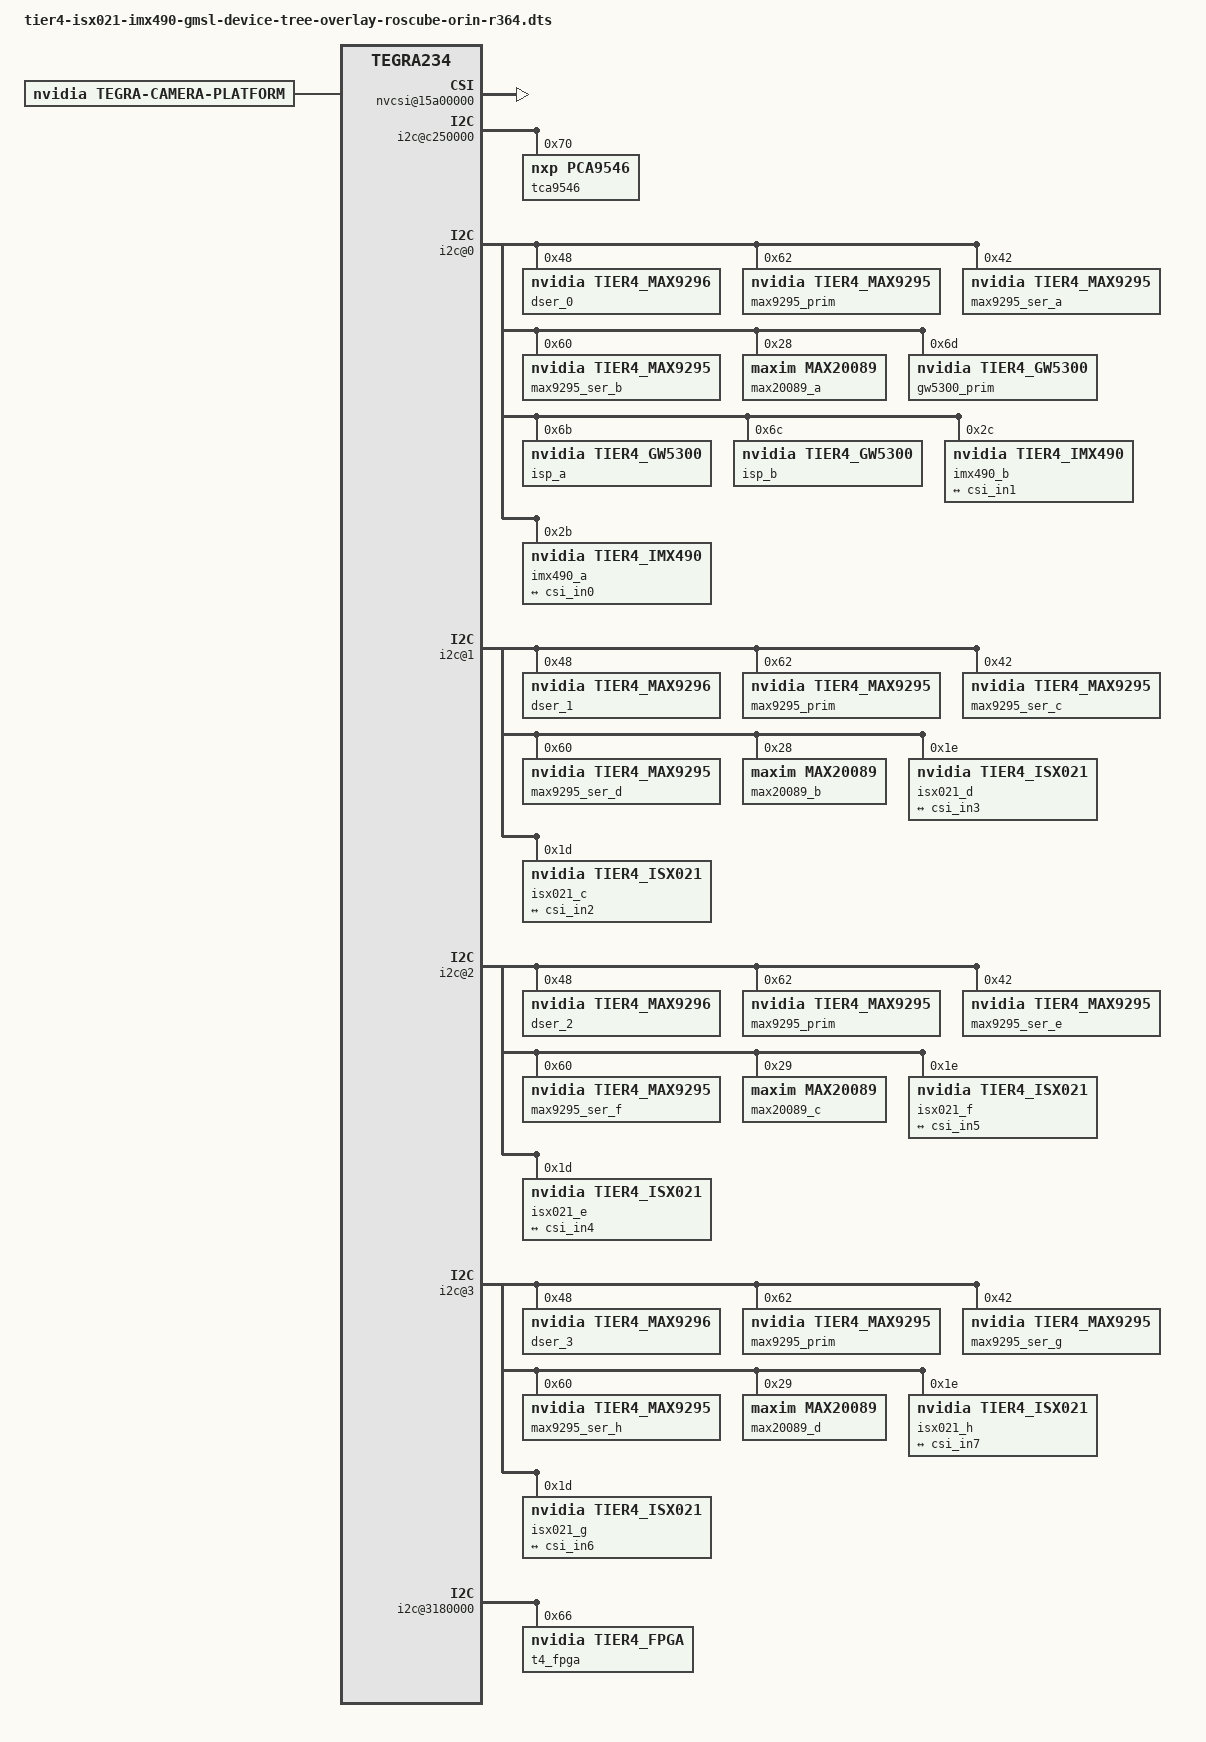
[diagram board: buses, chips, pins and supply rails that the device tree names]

/dts-v1/;
/plugin/;

/ {
    overlay-name = "TIERIV GMSL2 Camera Device Tree Overlay: C2x2 C1x6";
    jetson-header-name = "Jetson AGX CSI Connector";
    compatible = "nvidia,p3737-0000+p3701-0000", "nvidia,tegra234", "nvidia,tegra23x";

// ----- for VI -----

  fragment@1{
    target-path = "/tegra-capture-vi";
    __overlay__ {
      status = "okay";
      num-channels = <0x08>;
      ports {
        status = "okay";
        #address-cells = <1>;
        #size-cells = <0>;
        port@0 {
          status = "okay";
          reg = <0>;
          vi_in0: endpoint {
            status = "okay";
          };
        };
        port@1 {
          status = "okay";
          reg = <1>;
          vi_in1: endpoint {
            status = "okay";
          };
        };
        port@2 {
          status = "okay";
          reg = <2>;
          vi_in2: endpoint {
            status = "okay";
          };
        };
        port@3 {
          status = "okay";
          reg = <3>;
          vi_in3: endpoint {
            status = "okay";
          };
        };
        port@4 {
          status = "okay";
          reg = <4>;
          vi_in4: endpoint {
            status = "okay";
          };
        };
        port@5 {
          status = "okay";
          reg = <5>;
          vi_in5: endpoint {
            status = "okay";
          };
        };
        port@6 {
          status = "okay";
          reg = <6>;
          vi_in6: endpoint {
            status = "okay";
          };
        };
        port@7 {
          status = "okay";
          reg = <7>;
          vi_in7: endpoint {
            status = "okay";
          };
        };
      };
    };
  };

//diff view
  fragment@2{
    target-path = "/tegra-capture-vi/ports/port@0";
    __overlay__ {
      status = "okay";
    };
  };

  fragment@3{
    // target = vi_in0;
    target-path = "/tegra-capture-vi/ports/port@0/endpoint";
    __overlay__ {
      status = "okay";
      port-index = <0>;
      vc-id = <0>;
      bus-width = <4>;
      remote-endpoint = <&csi_out0>;
    };
  };

  fragment@4{
    target-path = "/tegra-capture-vi/ports/port@1";
    __overlay__ {
      status = "okay";
    };
  };

  fragment@5{
    // target = vi_in1;
    target-path = "/tegra-capture-vi/ports/port@1/endpoint";
    __overlay__ {
      status = "okay";
      vc-id = <1>;
      port-index = <0>;
      bus-width = <4>;
      remote-endpoint = <&csi_out1>;
    };
  };

  fragment@6{
    target-path = "/tegra-capture-vi/ports/port@2";
    __overlay__ {
      status = "okay";
    };
  };

  fragment@7{
    // target = vi_in2;
    target-path = "/tegra-capture-vi/ports/port@2/endpoint";
    __overlay__ {
      status = "okay";
      vc-id = <0>;
      port-index = <2>;
      bus-width = <4>;
      remote-endpoint = <&csi_out2>;
    };
  };

  fragment@8 {
    target-path = "/tegra-capture-vi/ports/port@3";
    __overlay__ {
      status = "okay";
    };
  };

  fragment@9 {
    // target = vi_in3;
    target-path = "/tegra-capture-vi/ports/port@3/endpoint";
    __overlay__ {
      status = "okay";
      vc-id = <1>;
      port-index = <2>;
      bus-width = <4>;
      remote-endpoint = <&csi_out3>;
    };
  };

  fragment@10 {
    target-path = "/tegra-capture-vi/ports/port@4";
    __overlay__ {
      status = "okay";
    };
  };

  fragment@11 {
    // target = vi_in4;
    target-path = "/tegra-capture-vi/ports/port@4/endpoint";
    __overlay__ {
      status = "okay";
      vc-id = <0>;
      port-index = <4>;
      bus-width = <4>;
      remote-endpoint = <&csi_out4>;
    };
  };

  fragment@12 {
    target-path = "/tegra-capture-vi/ports/port@5";
    __overlay__ {
      status = "okay";
    };
  };

  fragment@13 {
    // target = vi_in5;
    target-path = "/tegra-capture-vi/ports/port@5/endpoint";
    __overlay__ {
      status = "okay";
      vc-id = <1>;
      port-index = <4>;
      bus-width = <4>;
      remote-endpoint = <&csi_out5>;
    };
  };

  fragment@14 {
    target-path = "/tegra-capture-vi/ports/port@6";
    __overlay__ {
      status = "okay";
    };
  };

  fragment@15 {
    // target = vi_in6;
    target-path = "/tegra-capture-vi/ports/port@6/endpoint";
    __overlay__ {
      status = "okay";
      vc-id = <0>;
      port-index = <5>;
      bus-width = <4>;
      remote-endpoint = <&csi_out6>;
    };
  };

  fragment@16 {
    target-path = "/tegra-capture-vi/ports/port@7";
    __overlay__ {
      status = "okay";
    };
  };

  fragment@17 {
    // target = vi_in7;
    target-path = "/tegra-capture-vi/ports/port@7/endpoint";
    __overlay__ {
      status = "okay";
      vc-id = <1>;
      port-index = <5>;
      bus-width = <4>;
      remote-endpoint = <&csi_out7>;
    };
  };

// -----   NVCSI  ------

  fragment@19 {
    target-path = "/bus@0/host1x@13e00000/nvcsi@15a00000";
    __overlay__ {
        status = "okay";
        #address-cells = <1>;
        #size-cells = <0>;
        num-channels = <8>;
        channel@0 {
          status = "okay";
          reg = <0>;
          ports {
            status = "okay";
            #address-cells = <1>;
            #size-cells = <0>;
            port@0 {
              status = "okay";
              reg = <0>;
              csi_in0: endpoint@0 {
                status = "okay";
              };
            };
            port@1 {
              status = "okay";
              reg = <1>;
              csi_out0: endpoint@1 {
                status = "okay";
              };
            };
          };
        };
        channel@1 {
          status = "okay";
          reg = <1>;
          ports {
            status = "okay";
            #address-cells = <1>;
            #size-cells = <0>;
            port@0 {
              status = "okay";
              reg = <0>;
              csi_in1: endpoint@0 {
                status = "okay";
              };
            };
            port@1 {
              status = "okay";
              reg = <1>;
              csi_out1: endpoint@1 {
                status = "okay";
              };
            };
          };
        };
        channel@2 {
          status = "okay";
          reg = <2>;
          ports {
            status = "okay";
            #address-cells = <1>;
            #size-cells = <0>;
            port@0 {
              status = "okay";
              reg = <0>;
              csi_in2: endpoint@0 {
                status = "okay";
              };
            };
            port@1 {
              status = "okay";
              reg = <1>;
              csi_out2: endpoint@1 {
                status = "okay";
              };
            };
          };
        };
        channel@3 {
          status = "okay";
          reg = <3>;
          ports {
            status = "okay";
            #address-cells = <1>;
            #size-cells = <0>;
            port@0 {
              status = "okay";
              reg = <0>;
              csi_in3: endpoint@0 {
                status = "okay";
              };
            };
            port@1 {
              status = "okay";
              reg = <1>;
              csi_out3: endpoint@1 {
                status = "okay";
              };
            };
          };
        };
        channel@4 {
          status = "okay";
          reg = <4>;
          ports {
            status = "okay";
            #address-cells = <1>;
            #size-cells = <0>;
            port@0 {
              status = "okay";
              reg = <0>;
              csi_in4: endpoint@0 {
                status = "okay";
              };
            };
            port@1 {
              status = "okay";
              reg = <1>;
              csi_out4: endpoint@1 {
                status = "okay";
              };
            };
          };
        };
        channel@5 {
          status = "okay";
          reg = <5>;
          ports {
            status = "okay";
            #address-cells = <1>;
            #size-cells = <0>;
            port@0 {
              status = "okay";
              reg = <0>;
              csi_in5: endpoint@0 {
                status = "okay";
              };
            };
            port@1 {
              status = "okay";
              reg = <1>;
              csi_out5: endpoint@1 {
                status = "okay";
              };
            };
          };
        };
        channel@6 {
          status = "okay";
          reg = <6>;
          ports {
            status = "okay";
            #address-cells = <1>;
            #size-cells = <0>;
            port@0 {
              status = "okay";
              reg = <0>;
              csi_in6: endpoint@0 {
                status = "okay";
              };
            };
            port@1 {
              status = "okay";
              reg = <1>;
              csi_out6: endpoint@1 {
                status = "okay";
              };
            };
          };
        };
        channel@7 {
          status = "okay";
          reg = <7>;
          ports {
            status = "okay";
            #address-cells = <1>;
            #size-cells = <0>;
            port@0 {
              status = "okay";
              reg = <0>;
              csi_in7: endpoint@0 {
                status = "okay";
              };
            };
            port@1 {
              status = "okay";
              reg = <1>;
              csi_out7: endpoint@1 {
                status = "okay";
              };
            };
          };
        };
    };
  };


// channel@0

  fragment@20 {
    target-path = "/bus@0/host1x@13e00000/nvcsi@15a00000/channel@0";
    __overlay__ {
      status = "okay";
    };
  };

  fragment@21 {
    target-path = "/bus@0/host1x@13e00000/nvcsi@15a00000/channel@0/ports/port@0";
    __overlay__ {
      status = "okay";
    };
  };
  fragment@22 {
    // target = csi_in0
    target-path = "/bus@0/host1x@13e00000/nvcsi@15a00000/channel@0/ports/port@0/endpoint@0";
    __overlay__ {
      status = "okay";
      port-index = <0>;
      bus-width = <4>;
      remote-endpoint = <&imx490_out0>;
    };
  };

  fragment@23 {
    target-path = "/bus@0/host1x@13e00000/nvcsi@15a00000/channel@0/ports/port@1";
    __overlay__ {
      status = "okay";
    };
  };

  fragment@24 {
    // target = csi_out0
    target-path = "/bus@0/host1x@13e00000/nvcsi@15a00000/channel@0/ports/port@1/endpoint@1";
    __overlay__ {
      status = "okay";
      remote-endpoint = <&vi_in0>;
    };
  };

// channel@1

  fragment@25 {
    target-path = "/bus@0/host1x@13e00000/nvcsi@15a00000/channel@1";
    __overlay__ {
      status = "okay";
    };
  };

  fragment@26 {
    target-path = "/bus@0/host1x@13e00000/nvcsi@15a00000/channel@1/ports/port@0";
    __overlay__ {
      status = "okay";
    };
  };

  fragment@27 {
    // target = csi_in1
    target-path = "/bus@0/host1x@13e00000/nvcsi@15a00000/channel@1/ports/port@0/endpoint@0";
    __overlay__ {
      status = "okay";
      port-index = <0>;
      bus-width = <4>;
      remote-endpoint = <&imx490_out1>;
    };
  };

  fragment@28 {
    // target = csi_out1
    target-path = "/bus@0/host1x@13e00000/nvcsi@15a00000/channel@1/ports/port@1/endpoint@1";
    __overlay__ {
      status = "okay";
      remote-endpoint = <&vi_in1>;
    };
  };

// channel@2

  fragment@29 {
    target-path = "/bus@0/host1x@13e00000/nvcsi@15a00000/channel@2";
    __overlay__ {
      status = "okay";
    };
  };

  fragment@30 {
    target-path = "/bus@0/host1x@13e00000/nvcsi@15a00000/channel@2/ports/port@0";
    __overlay__ {
      status = "okay";
    };
  };

  fragment@31 {
    // target = csi_in2
    target-path = "/bus@0/host1x@13e00000/nvcsi@15a00000/channel@2/ports/port@0/endpoint@0";
    __overlay__ {
      status = "okay";
      port-index = <2>;
      bus-width = <4>;
      remote-endpoint = <&isx021_out2>;
    };
  };

  fragment@32 {
    target-path = "/bus@0/host1x@13e00000/nvcsi@15a00000/channel@2/ports/port@1";
    __overlay__ {
      status = "okay";
    };
  };

  fragment@33 {
    // target = csi_out2
    target-path = "/bus@0/host1x@13e00000/nvcsi@15a00000/channel@2/ports/port@1/endpoint@1";
    __overlay__ {
      status = "okay";
      remote-endpoint = <&vi_in2>;
    };
  };

// channel@3

  fragment@34 {
    target-path = "/bus@0/host1x@13e00000/nvcsi@15a00000/channel@3";
    __overlay__ {
      status = "okay";
    };
  };

  fragment@35 {
    target-path = "/bus@0/host1x@13e00000/nvcsi@15a00000/channel@3/ports/port@0";
    __overlay__ {
      status = "okay";
    };
  };

  fragment@36 {
    // target = csi_in3
    target-path = "/bus@0/host1x@13e00000/nvcsi@15a00000/channel@3/ports/port@0/endpoint@0";
    __overlay__ {
      status = "okay";
      port-index = <2>;
      bus-width = <4>;
      remote-endpoint = <&isx021_out3>;
    };
  };

  fragment@37 {
    target-path = "/bus@0/host1x@13e00000/nvcsi@15a00000/channel@3/ports/port@1";
    __overlay__ {
      status = "okay";
    };
  };

  fragment@38 {
    // target = csi_out3
    target-path = "/bus@0/host1x@13e00000/nvcsi@15a00000/channel@3/ports/port@1/endpoint@1";
    __overlay__ {
      status = "okay";
      remote-endpoint = <&vi_in3>;
    };
  };

// channel@4

  fragment@39 {
    target-path = "/bus@0/host1x@13e00000/nvcsi@15a00000/channel@4";
    __overlay__ {
      status = "okay";
    };
  };

  fragment@40 {
    target-path = "/bus@0/host1x@13e00000/nvcsi@15a00000/channel@4/ports/port@0";
    __overlay__ {
      status = "okay";
    };
  };

  fragment@41 {
    // target = csi_in4
    target-path = "/bus@0/host1x@13e00000/nvcsi@15a00000/channel@4/ports/port@0/endpoint@0";
    __overlay__ {
      status = "okay";
      port-index = <4>;
      bus-width = <4>;
      remote-endpoint = <&isx021_out4>;
    };
  };

  fragment@42 {
    target-path = "/bus@0/host1x@13e00000/nvcsi@15a00000/channel@4/ports/port@1";
    __overlay__ {
      status = "okay";
    };
  };

  fragment@43 {
    // target = csi_out4
    target-path = "/bus@0/host1x@13e00000/nvcsi@15a00000/channel@4/ports/port@1/endpoint@1";
    __overlay__ {
      status = "okay";
      remote-endpoint = <&vi_in4>;
    };
  };

// channel@5

  fragment@44 {
    target-path = "/bus@0/host1x@13e00000/nvcsi@15a00000/channel@5";
    __overlay__ {
      status = "okay";
    };
  };

  fragment@45 {
    target-path = "/bus@0/host1x@13e00000/nvcsi@15a00000/channel@5/ports/port@0";
    __overlay__ {
      status = "okay";
    };
  };

  fragment@46 {
    // target = csi_in5
    target-path = "/bus@0/host1x@13e00000/nvcsi@15a00000/channel@5/ports/port@0/endpoint@0";
    __overlay__ {
      status = "okay";
      port-index = <4>;
      bus-width = <4>;
      remote-endpoint = <&isx021_out5>;
    };
  };

  fragment@47 {
    target-path = "/bus@0/host1x@13e00000/nvcsi@15a00000/channel@5/ports/port@1";
    __overlay__ {
      status = "okay";
    };
  };

  fragment@48 {
    // target = csi_out5
    target-path = "/bus@0/host1x@13e00000/nvcsi@15a00000/channel@5/ports/port@1/endpoint@1";
    __overlay__ {
      status = "okay";
      remote-endpoint = <&vi_in5>;
    };
  };

// channel@6

  fragment@49 {
    // target = csi_in6
    target-path = "/bus@0/host1x@13e00000/nvcsi@15a00000/channel@6/ports/port@0/endpoint@0";
    __overlay__ {
      status = "okay";
      port-index = <6>;
      bus-width = <4>;
      remote-endpoint = <&isx021_out6>;
    };
  };

  fragment@50 {
    target-path = "/bus@0/host1x@13e00000/nvcsi@15a00000/channel@6/ports/port@1";
    __overlay__ {
      status = "okay";
    };
  };

  fragment@51 {
    // target = csi_out6
    target-path = "/bus@0/host1x@13e00000/nvcsi@15a00000/channel@6/ports/port@1/endpoint@1";
    __overlay__ {
      status = "okay";
      remote-endpoint = <&vi_in6>;
    };
  };

// channel@7

  fragment@52 {
    // target = csi_in7
    target-path = "/bus@0/host1x@13e00000/nvcsi@15a00000/channel@7/ports/port@0/endpoint@0";
    __overlay__ {
      status = "okay";
      port-index = <6>;
      bus-width = <4>;
      remote-endpoint = <&isx021_out7>;
    };
  };

  fragment@53 {
    target-path = "/bus@0/host1x@13e00000/nvcsi@15a00000/channel@7/ports/port@1";
    __overlay__ {
      status = "okay";
    };
  };

  fragment@54 {
    // target = csi_out7
    target-path = "/bus@0/host1x@13e00000/nvcsi@15a00000/channel@7/ports/port@1/endpoint@1";
    __overlay__ {
      status = "okay";
      remote-endpoint = <&vi_in7>;
    };
  };

  fragment@55 {
    target-path = "/bus@0/host1x@13e00000/nvcsi@15a00000";
    __overlay__ {
      status = "okay";
      num-channels = <8>;
    };
  };

 fragment@56{
   target-path = "/bus@0/host1x@13e00000/vi1@14c00000";
   __overlay__ {
     status = "okay";
   };
 };

  fragment@57{
    target-path = "/bus@0/host1x@13e00000/vi0@15c00000";
    __overlay__ {
      status = "okay";
    };
  };



// ----- Camera modules -----

  fragment@70 {
    //tcp
    target-path = "/";
    __overlay__ {
        tegra-camera-platform {
          compatible = "nvidia, tegra-camera-platform";
          status = "okay";
          num_csi_lanes = <16>;
          max_lane_speed = <4000000>;
          min_bits_per_pixel = <10>;
          vi_peak_byte_per_pixel = <2>;
          vi_bw_margin_pct = <25>;
          max_pixel_rate = <160000>;
          isp_peak_byte_per_pixel = <5>;
          isp_bw_margin_pct = <25>;

          modules {
            module0 {
              drivernode0 {
              };
            };
            module1 {
              drivernode0 {
              };
            };
            module2 {
              drivernode0 {
              };
            };
            module3 {
              drivernode0 {
              };
            };
            module4 {
              drivernode0 {
              };
            };
            module5 {
              drivernode0 {
              };
            };
            module6 {
              drivernode0 {
              };
            };
            module7 {
              drivernode0 {
              };
            };
          };
        };
    };
  };

  fragment@71 {
    target-path = "/tegra-camera-platform/modules/module0";
    __overlay__ {
      badge = "imx490_rear";
      position = "rear";
      orientation = "1";
      status = "okay";
    };
  };

  fragment@72 {
    target-path = "/tegra-camera-platform/modules/module0/drivernode0";
    __overlay__ {
      status = "okay";
      pcl_id = "v4l2_sensor";
      sysfs-device-tree = "/sys/firmware/devicetree/base/bus@0/i2c@c250000/tca9546@70/i2c@0/imx490_a@2b";
    };
  };

  fragment@73 {
    target-path = "/tegra-camera-platform/modules/module1";
    __overlay__ {
      badge = "imx490_front";
      position = "front";
      orientation = "1";
      status = "okay";
    };
  };

  fragment@74 {
    target-path = "/tegra-camera-platform/modules/module1/drivernode0";
    __overlay__ {
      status = "okay";
      pcl_id = "v4l2_sensor";
      sysfs-device-tree = "/sys/firmware/devicetree/base/bus@0/i2c@c250000/tca9546@70/i2c@0/imx490_b@2c";
    };
  };

  fragment@75 {
    target-path = "/tegra-camera-platform/modules/module2";
    __overlay__ {
      badge = "isx021_topright";
      position = "topright";
      orientation = "1";
      status = "okay";
    };
  };

  fragment@76 {
    target-path = "/tegra-camera-platform/modules/module2/drivernode0";
    __overlay__ {
      status = "okay";
      pcl_id = "v4l2_sensor";
      sysfs-device-tree = "/sys/firmware/devicetree/base/bus@0/i2c@c250000/tca9546@70/i2c@1/isx021_c@1d";
    };
  };

  fragment@77 {
    target-path = "/tegra-camera-platform/modules/module3";
    __overlay__ {
      badge = "isx021_bottomright";
      position = "bottomright";
      orientation = "1";
      status = "okay";
    };
  };

  fragment@78 {
    target-path = "/tegra-camera-platform/modules/module3/drivernode0";
    __overlay__ {
      status = "okay";
      pcl_id = "v4l2_sensor";
      sysfs-device-tree = "/sys/firmware/devicetree/base/bus@0/i2c@c250000/tca9546@70/i2c@1/isx021_d@1e";
    };
  };

  fragment@79 {
    target-path = "/tegra-camera-platform/modules/module4";
    __overlay__ {
      badge = "isx021_topleft";
      position = "topleft";
      orientation = "1";
      status = "okay";
    };
  };

  fragment@80 {
    target-path = "/tegra-camera-platform/modules/module4/drivernode0";
    __overlay__ {
      status = "okay";
      pcl_id = "v4l2_sensor";
      sysfs-device-tree = "/sys/firmware/devicetree/base/bus@0/i2c@c250000/tca9546@70/i2c@2/isx021_e@1d";
    };
  };

  fragment@81 {
    target-path = "/tegra-camera-platform/modules/module5";
    __overlay__ {
      badge = "isx021_centerright";
      position = "centerright";
      orientation = "1";
      status = "okay";
    };
  };

  fragment@82 {
    target-path = "/tegra-camera-platform/modules/module5/drivernode0";
    __overlay__ {
      status = "okay";
      pcl_id = "v4l2_sensor";
      sysfs-device-tree = "/sys/firmware/devicetree/base/bus@0/i2c@c250000/tca9546@70/i2c@2/isx021_f@1e";
    };
  };

  fragment@83 {
    target-path = "/tegra-camera-platform/modules/module6";
    __overlay__ {
      badge = "isx021_centerleft";
      position = "centerleft";
      orientation = "1";
      status = "okay";
    };
  };

  fragment@84 {
    target-path = "/tegra-camera-platform/modules/module6/drivernode0";
    __overlay__ {
      status = "okay";
      pcl_id = "v4l2_sensor";
      sysfs-device-tree = "/sys/firmware/devicetree/base/bus@0/i2c@c250000/tca9546@70/i2c@3/isx021_g@1d";
    };
  };

  fragment@85 {
    target-path = "/tegra-camera-platform/modules/module7";
    __overlay__ {
      badge = "isx021_bottomleftt";
      position = "bottomleft";
      orientation = "1";
      status = "okay";
    };
  };

  fragment@86 {
    target-path = "/tegra-camera-platform/modules/module7/drivernode0";
    __overlay__ {
      status = "okay";
      pcl_id = "v4l2_sensor";
      sysfs-device-tree = "/sys/firmware/devicetree/base/bus@0/i2c@c250000/tca9546@70/i2c@3/isx021_h@1e";
    };
  };


  fragment@90 {
    // declare the i2c switch for the four i2c clients
    target-path = "/bus@0/i2c@c250000";
    __overlay__ {
      tca9546@70 {
        status = "okay";
        #address-cells = <1>;
        #size-cells = <0>;
        compatible = "nxp,pca9546";
        reg = <0x70>;
        skip_mux_detect = "yes";
        force_bus_start = <0x1e>;
        i2c@0 {
          status = "okay";
          reg = <0>;
        };
        i2c@1 {
          status = "okay";
          reg = <1>;
        };
        i2c@2 {
          status = "okay";
          reg = <2>;
        };
        i2c@3 {
          status = "okay";
          reg = <3>;
        };
      };
    };
  };

  fragment@91{
    //cami2c/i2c@0
    target-path = "/bus@0/i2c@c250000/tca9546@70/i2c@0";
    __overlay__ {
      i2c-mux,deselect-on-exit;
      #address-cells = <1>;
      #size-cells = <0>;
      status = "okay";
      reg = <0>;

      dser_0: max9296@48 {
        compatible = "nvidia,tier4_max9296";
        reg = <0x48>;
        status = "okay";
        csi-mode = "2x4";
        max-src = <2>;
        //reset-gpios = <&tegra_main_gpio CAM0_PWDN GPIO_ACTIVE_HIGH>;
        //reset-gpios = <&tegra_main_gpio 0x3E 0x0>;
      };

      max9295_prim@62 {
        compatible = "nvidia,tier4_max9295";
        status = "okay";
        reg = <0x62>;
        is-prim-ser;
      };
      max9295_ser_a: max9295_a@42 {
        compatible = "nvidia,tier4_max9295";
        reg = <0x42>;
        nvidia,gmsl-dser-device = <&dser_0>;
      };

      max9295_ser_b: max9295_b@60 {
        compatible = "nvidia,tier4_max9295";
        status = "okay";
        reg = <0x60>;
        nvidia,gmsl-dser-device = <&dser_0>;
      };

      max20089_a: max20089@28 {
        status = "okay";
        compatible = "maxim,max20089";
        reg = <0x28>;
      };

      gw5300_prim@6d {
          compatible = "nvidia,tier4_gw5300";
          reg = <0x6d>;
          is-prim-isp;
      };

      isp_a: gw5300_a@6b {
          compatible = "nvidia,tier4_gw5300";
          reg = <0x6b>;
      };

      isp_b: gw5300_b@6c {
          compatible = "nvidia,tier4_gw5300";
          reg = <0x6c>;
      };

      imx490_b@2c {
        status = "okay";
        compatible = "nvidia,tier4_imx490";
        reg = <0x2c>;
        def-addr = <0x1a>;
        mclk = "extperiph1";
        clocks = <&bpmp 36U>, <&bpmp 36U>;
        clock-names = "extperiph1", "pllp_grtba";
        nvidia,isp-device = <&isp_b>;           // for C2/C3 camera
        nvidia,gmsl-ser-device = <&max9295_ser_b>;
        nvidia,gmsl-dser-device = <&dser_0>;
        nvidia,fpga-device  = <&t4_fpga>;
        nvidia,cam-power-protector  = <&max20089_a>;
        physical_w = "15.0";
        physical_h = "12.5";
        reg_mux = <0>;

        sensor_model ="imx490";
        fsync-mode = "false";
        distortion-correction = "false";
        auto-exposure = "true";
        post_crop_frame_drop = "0";
        use_decibel_gain = "true";

        /* enable CID_SENSOR_MODE_ID for sensor modes selection */
        use_sensor_mode_id = "true";

        mode0 {/*mode IMX490_MODE_2880X1860_CROP_30FPS*/
          mclk_khz = "24000";
          num_lanes = "4";
          tegra_sinterface = "serial_a";
          vc_id = "1";
          discontinuous_clk = "no";
          dpcm_enable = "false";
          cil_settletime = "0";
          dynamic_pixel_bit_depth = "16";
          csi_pixel_bit_depth = "16";
          mode_type = "yuv";
          pixel_phase = "uyvy";

          active_w = "2880";
          active_h = "1860";
          readout_orientation = "0";
          line_length = "2250";
          inherent_gain = "1";
          pix_clk_hz = "757";
          serdes_pix_clk_hz = "375000000";    // MIPI CSI clock 1500Mhz

          gain_factor = "10";
          min_gain_val = "0";                         /* dB */
          max_gain_val = "300";                       /* dB */
          step_gain_val = "3";                        /* 0.3 */
          default_gain = "0";
          min_hdr_ratio = "1";
          max_hdr_ratio = "1";
          framerate_factor = "1000000";
          min_framerate = "30000000";
          max_framerate = "30000000";
          step_framerate = "1";
          default_framerate = "30000000";
          exposure_factor = "1000000";
          min_exp_time = "24";                         /* us 1 line */
          max_exp_time = "33333";
          step_exp_time = "1";
          default_exp_time = "33333";                 /* us */
          embedded_metadata_height = "0";
        };

        ports {
          #address-cells = <1>;
          #size-cells = <0>;
          port@0 {
            reg = <0>;
            imx490_out1: endpoint {
              vc-id = <1>;
              port-index = <0>;
              bus-width = <4>;
              remote-endpoint = <&csi_in1>;
            };
          };
        };
        gmsl-link {
          src-csi-port = "b";     /* Port at which sensor is connected to its serializer device. */
          dst-csi-port = "a";     /* Destination CSI port on the Jetson side, connected at deserializer. */
           serdes-csi-link = "b";  /* GMSL link sensor/serializer connected */
          csi-mode = "1x4";       /*  to sensor CSI mode. */
          st-vc = <0>;            /* Sensor source default VC ID: 0 unless overridden by sensor. */
          vc-id = <1>;            /* Destination VC ID, assigned to sensor stream by deserializer. */
          num-lanes = <4>;        /* Number of CSI lanes used. */
          streams = "ued-u1","yuv8"; /* Types of streams sensor is streaming. */
        };
      };
      imx490_a@2b {
        status = "okay";
        compatible = "nvidia,tier4_imx490";
        reg = <0x2b>;
        def-addr = <0x1a>;
        mclk = "extperiph1";
        clocks = <&bpmp 36U>, <&bpmp 36U>;
        clock-names = "extperiph1", "pllp_grtba";
        nvidia,isp-device = <&isp_a>;           // for C2/C3 camera
        nvidia,gmsl-ser-device = <&max9295_ser_a>;
        nvidia,gmsl-dser-device = <&dser_0>;
        nvidia,fpga-device  = <&t4_fpga>;
        nvidia,cam-power-protector  = <&max20089_a>;
        physical_w = "15.0";
        physical_h = "12.5";
        reg_mux = <0>;

        sensor_model ="imx490";
        fsync-mode = "false";
        distortion-correction = "false";
        auto-exposure = "true";
        post_crop_frame_drop = "0";
        use_decibel_gain = "true";

        /* enable CID_SENSOR_MODE_ID for sensor modes selection */
        use_sensor_mode_id = "true";

        mode0 {/*mode IMX490_MODE_2880X1860_CROP_30FPS*/
          mclk_khz = "24000";
          num_lanes = "4";
          tegra_sinterface = "serial_a";
          vc_id = "0";
          discontinuous_clk = "no";
          dpcm_enable = "false";
          cil_settletime = "0";
          dynamic_pixel_bit_depth = "16";
          csi_pixel_bit_depth = "16";
          mode_type = "yuv";
          pixel_phase = "uyvy";

          active_w = "2880";
          active_h = "1860";
          readout_orientation = "0";
          line_length = "2250";
          inherent_gain = "1";
          pix_clk_hz = "757";
          serdes_pix_clk_hz = "375000000";    // MIPI CSI clock 1500Mhz

          gain_factor = "10";
          min_gain_val = "0";                         /* dB */
          max_gain_val = "300";                       /* dB */
          step_gain_val = "3";                        /* 0.3 */
          default_gain = "0";
          min_hdr_ratio = "1";
          max_hdr_ratio = "1";
          framerate_factor = "1000000";
          min_framerate = "30000000";
          max_framerate = "30000000";
          step_framerate = "1";
          default_framerate = "30000000";
          exposure_factor = "1000000";
          min_exp_time = "24";                         /* us 1 line */
          max_exp_time = "33333";
          step_exp_time = "1";
          default_exp_time = "33333";                 /* us */
          embedded_metadata_height = "0";
        };

        ports {
          #address-cells = <1>;
          #size-cells = <0>;
          port@0 {
            reg = <0>;
            imx490_out0: endpoint {
              vc-id = <0>;
              port-index = <0>;
              bus-width = <4>;
              remote-endpoint = <&csi_in0>;
            };
          };
        };
        gmsl-link {
          src-csi-port = "b";     /* Port at which sensor is connected to its serializer device. */
          dst-csi-port = "a";     /* Destination CSI port on the Jetson side, connected at deserializer. */
          serdes-csi-link = "a";  /* GMSL link sensor/serializer connected */
          csi-mode = "1x4";       /*  to sensor CSI mode. */
          st-vc = <0>;            /* Sensor source default VC ID: 0 unless overridden by sensor. */
          vc-id = <0>;            /* Destination VC ID, assigned to sensor stream by deserializer. */
          num-lanes = <4>;        /* Number of CSI lanes used. */
          streams = "ued-u1","yuv8"; /* Types of streams sensor is streaming. */
        };
      };
    };
  };
  fragment@92{
    //cami2c/i2c@1
    target-path = "/bus@0/i2c@c250000/tca9546@70/i2c@1";
    __overlay__ {
      i2c-mux,deselect-on-exit;
      #address-cells = <1>;
      #size-cells = <0>;
      status = "okay";
      reg = <1>;

      dser_1: max9296@48 {
        compatible = "nvidia,tier4_max9296";
        reg = <0x48>;
        status = "okay";
        csi-mode = "2x4";
        max-src = <2>;
        //reset-gpios = <&tegra_main_gpio CAM0_PWDN GPIO_ACTIVE_HIGH>;
        //reset-gpios = <&tegra_main_gpio 0x3E 0x0>;
      };

      max9295_prim@62 {
        compatible = "nvidia,tier4_max9295";
        status = "okay";
        reg = <0x62>;
        is-prim-ser;
      };
      max9295_ser_c: max9295_a@42 {
        compatible = "nvidia,tier4_max9295";
        reg = <0x42>;
        nvidia,gmsl-dser-device = <&dser_1>;
      };

      max9295_ser_d: max9295_b@60 {
        compatible = "nvidia,tier4_max9295";
        status = "okay";
        reg = <0x60>;
        nvidia,gmsl-dser-device = <&dser_1>;
      };

      max20089_b: max20089@28 {
        status = "okay";
        compatible = "maxim,max20089";
        reg = <0x28>;
      };

      isx021_d@1e {
        status = "okay";
        compatible = "nvidia,tier4_isx021";
        def-addr = <0x1a>;
        mclk = "extperiph1";
        clocks = <&bpmp 36U>, <&bpmp 36U>;
        clock-names = "extperiph1", "pllp_grtba";
        nvidia,gmsl-ser-device = <&max9295_ser_d>;
        nvidia,gmsl-dser-device = <&dser_1>;
        nvidia,fpga-device  = <&t4_fpga>;
        nvidia,cam-power-protector  = <&max20089_b>;
        reg = <0x1e>;
        physical_w = "15.0";
        physical_h = "12.5";
        reg_mux = <1>;

        sensor_model ="isx021";
        fsync-mode = "false";
        distortion-correction = "false";
        auto-exposure = "true";
        post_crop_frame_drop = "0";
        use_decibel_gain = "true";

        /* enable CID_SENSOR_MODE_ID for sensor modes selection */
        use_sensor_mode_id = "false";

        mode0 {
          /*mode ISX021_MODE_1920X1280_CROP_30FPS*/
          mclk_khz = "24000";
          num_lanes = "4";
          tegra_sinterface = "serial_c";
          vc_id = "1";
          discontinuous_clk = "no";
          dpcm_enable = "false";
          cil_settletime = "0";
          dynamic_pixel_bit_depth = "16";
          csi_pixel_bit_depth = "16";
          mode_type = "yuv";
          pixel_phase = "uyvy";

          active_w = "1920";
          active_h = "1280";
          readout_orientation = "0";
          line_length = "2250";
          inherent_gain = "1";

          pix_clk_hz = "94500000";
          serdes_pix_clk_hz = "375000000";    // MIPI CSI clock 1500Mhz

          gain_factor = "10";
          min_gain_val = "0";                   /* dB */
          max_gain_val = "300";                 /* dB */
          step_gain_val = "3";                  /* 0.3 */
          default_gain = "0";
          min_hdr_ratio = "1";
          max_hdr_ratio = "1";
          framerate_factor = "1000000";
          min_framerate = "30000000";
          max_framerate = "30000000";
          step_framerate = "1";
          default_framerate = "30000000";
          exposure_factor = "1000000";
          min_exp_time = "24";                  /* us 1 line */
          max_exp_time = "33333";
          step_exp_time = "1";
          default_exp_time = "33333";           /* us */
          embedded_metadata_height = "0";
        };
        mode1 {
          /*mode ISX021_MODE_1920X1280_CROP_30FPS  for Front Embedded data */
          mclk_khz = "24000";
          num_lanes = "4";
          tegra_sinterface = "serial_c";
          vc_id = "1";
          discontinuous_clk = "no";
          dpcm_enable = "false";
          cil_settletime = "0";
          dynamic_pixel_bit_depth = "16";
          csi_pixel_bit_depth = "16";
          mode_type = "yuv";
          pixel_phase = "uyvy";
          active_w = "1920";
          active_h = "1281";
          readout_orientation = "0";
          line_length = "2250";
          inherent_gain = "1";
          pix_clk_hz = "94500000";
          serdes_pix_clk_hz = "375000000";      /* MIPI CSI clock 1500Mhz */
          gain_factor = "10";
          min_gain_val = "0";                   /* dB */
          max_gain_val = "300";                 /* dB */
          step_gain_val = "3";                  /* 0.3 */
          default_gain = "0";
          min_hdr_ratio = "1";
          max_hdr_ratio = "1";
          framerate_factor = "1000000";
          min_framerate = "30000000";
          max_framerate = "30000000";
          step_framerate = "1";
          default_framerate = "30000000";
          exposure_factor = "1000000";
          min_exp_time = "24";                  /* us 1 line */
          max_exp_time = "33333";
          step_exp_time = "1";
          default_exp_time = "33333";           /* us */
          embedded_metadata_height = "0";
        };
        mode2 {
          /*mode ISX021_MODE_1920X1280_CROP_30FPS  for Rear Embedded data */
          mclk_khz = "24000";
          num_lanes = "4";
          tegra_sinterface = "serial_c";
          vc_id = "1";
          discontinuous_clk = "no";
          dpcm_enable = "false";
          cil_settletime = "0";
          dynamic_pixel_bit_depth = "16";
          csi_pixel_bit_depth = "16";
          mode_type = "yuv";
          pixel_phase = "uyvy";
          active_w = "1920";
          active_h = "1294";
          readout_orientation = "0";
          line_length = "2250";
          inherent_gain = "1";
          pix_clk_hz = "94500000";
          serdes_pix_clk_hz = "375000000";      /* MIPI CSI clock 1500Mhz */
          gain_factor = "10";
          min_gain_val = "0";                   /* dB */
          max_gain_val = "300";                 /* dB */
          step_gain_val = "3";                  /* 0.3 */
          default_gain = "0";
          min_hdr_ratio = "1";
          max_hdr_ratio = "1";
          framerate_factor = "1000000";
          min_framerate = "30000000";
          max_framerate = "30000000";
          step_framerate = "1";
          default_framerate = "30000000";
          exposure_factor = "1000000";
          min_exp_time = "24";                  /* us 1 line */
          max_exp_time = "33333";
          step_exp_time = "1";
          default_exp_time = "33333";           /* us */
          embedded_metadata_height = "0";
        };
        mode3 {
          /*mode ISX021_MODE_1920X1280_CROP_30FPS  for Front and Rear Embedded data */
          mclk_khz = "24000";
          num_lanes = "4";
          tegra_sinterface = "serial_c";
          vc_id = "1";
          discontinuous_clk = "no";
          dpcm_enable = "false";
          cil_settletime = "0";
          dynamic_pixel_bit_depth = "16";
          csi_pixel_bit_depth = "16";
          mode_type = "yuv";
          pixel_phase = "uyvy";
          active_w = "1920";
          active_h = "1295";
          readout_orientation = "0";
          line_length = "2250";
          inherent_gain = "1";
          pix_clk_hz = "94500000";
          serdes_pix_clk_hz = "375000000";      /* MIPI CSI clock 1500Mhz */
          gain_factor = "10";
          min_gain_val = "0";                   /* dB */
          max_gain_val = "300";                 /* dB */
          step_gain_val = "3";                  /* 0.3 */
          default_gain = "0";
          min_hdr_ratio = "1";
          max_hdr_ratio = "1";
          framerate_factor = "1000000";
          min_framerate = "30000000";
          max_framerate = "30000000";
          step_framerate = "1";
          default_framerate = "30000000";
          exposure_factor = "1000000";
          min_exp_time = "24";                  /* us 1 line */
          max_exp_time = "33333";
          step_exp_time = "1";
          default_exp_time = "33333";           /* us */
          embedded_metadata_height = "0";
        };

        ports {
          #address-cells = <1>;
          #size-cells = <0>;
          port@0 {
            reg = <0>;
            isx021_out3: endpoint {
              vc-id = <1>;
              port-index = <2>;
              bus-width = <4>;
              remote-endpoint = <&csi_in3>;
            };
          };
        };

        gmsl-link {
          src-csi-port = "b";           /* Port at which sensor is connected to its serializer device. */
          dst-csi-port = "a";           /* Destination CSI port on the Jetson side, connected at deserializer. */
           serdes-csi-link = "b";        /* GMSL link sensor/serializer connected */
          csi-mode = "1x4";             /*  to sensor CSI mode. */
          st-vc = <0>;                  /* Sensor source default VC ID: 0 unless overridden by sensor. */
          vc-id = <1>;                  /* Destination VC ID, assigned to sensor stream by deserializer. */
          num-lanes = <4>;              /* Number of CSI lanes used. */
          streams = "ued-u1", "yuv8";   /* Types of streams sensor is streaming. */
        };
      };
      isx021_c@1d {
        status = "okay";
        compatible = "nvidia,tier4_isx021";
        def-addr = <0x1a>;
        mclk = "extperiph1";
        clocks = <&bpmp 36U>, <&bpmp 36U>;
        clock-names = "extperiph1", "pllp_grtba";
        nvidia,gmsl-ser-device = <&max9295_ser_c>;
        nvidia,gmsl-dser-device = <&dser_1>;
        nvidia,fpga-device  = <&t4_fpga>;
        nvidia,cam-power-protector  = <&max20089_b>;
        reg = <0x1d>;
        physical_w = "15.0";
        physical_h = "12.5";
        reg_mux = <1>;

        sensor_model ="isx021";
        fsync-mode = "false";
        distortion-correction = "false";
        auto-exposure = "true";
        post_crop_frame_drop = "0";
        use_decibel_gain = "true";

        /* enable CID_SENSOR_MODE_ID for sensor modes selection */
        use_sensor_mode_id = "false";

        mode0 {
          /*mode ISX021_MODE_1920X1280_CROP_30FPS*/
          mclk_khz = "24000";
          num_lanes = "4";
          tegra_sinterface = "serial_c";
          vc_id = "0";
          discontinuous_clk = "no";
          dpcm_enable = "false";
          cil_settletime = "0";
          dynamic_pixel_bit_depth = "16";
          csi_pixel_bit_depth = "16";
          mode_type = "yuv";
          pixel_phase = "uyvy";

          active_w = "1920";
          active_h = "1280";
          readout_orientation = "0";
          line_length = "2250";
          inherent_gain = "1";

          pix_clk_hz = "94500000";
          serdes_pix_clk_hz = "375000000";    // MIPI CSI clock 1500Mhz

          gain_factor = "10";
          min_gain_val = "0";                   /* dB */
          max_gain_val = "300";                 /* dB */
          step_gain_val = "3";                  /* 0.3 */
          default_gain = "0";
          min_hdr_ratio = "1";
          max_hdr_ratio = "1";
          framerate_factor = "1000000";
          min_framerate = "30000000";
          max_framerate = "30000000";
          step_framerate = "1";
          default_framerate = "30000000";
          exposure_factor = "1000000";
          min_exp_time = "24";                  /* us 1 line */
          max_exp_time = "33333";
          step_exp_time = "1";
          default_exp_time = "33333";           /* us */
          embedded_metadata_height = "0";
        };
        mode1 {
          /*mode ISX021_MODE_1920X1280_CROP_30FPS  for Front Embedded data */
          mclk_khz = "24000";
          num_lanes = "4";
          tegra_sinterface = "serial_c";
          vc_id = "0";
          discontinuous_clk = "no";
          dpcm_enable = "false";
          cil_settletime = "0";
          dynamic_pixel_bit_depth = "16";
          csi_pixel_bit_depth = "16";
          mode_type = "yuv";
          pixel_phase = "uyvy";
          active_w = "1920";
          active_h = "1281";
          readout_orientation = "0";
          line_length = "2250";
          inherent_gain = "1";
          pix_clk_hz = "94500000";
          serdes_pix_clk_hz = "375000000";      /* MIPI CSI clock 1500Mhz */
          gain_factor = "10";
          min_gain_val = "0";                   /* dB */
          max_gain_val = "300";                 /* dB */
          step_gain_val = "3";                  /* 0.3 */
          default_gain = "0";
          min_hdr_ratio = "1";
          max_hdr_ratio = "1";
          framerate_factor = "1000000";
          min_framerate = "30000000";
          max_framerate = "30000000";
          step_framerate = "1";
          default_framerate = "30000000";
          exposure_factor = "1000000";
          min_exp_time = "24";                  /* us 1 line */
          max_exp_time = "33333";
          step_exp_time = "1";
          default_exp_time = "33333";           /* us */
          embedded_metadata_height = "0";
        };
        mode2 {
          /*mode ISX021_MODE_1920X1280_CROP_30FPS  for Rear Embedded data */
          mclk_khz = "24000";
          num_lanes = "4";
          tegra_sinterface = "serial_c";
          vc_id = "0";
          discontinuous_clk = "no";
          dpcm_enable = "false";
          cil_settletime = "0";
          dynamic_pixel_bit_depth = "16";
          csi_pixel_bit_depth = "16";
          mode_type = "yuv";
          pixel_phase = "uyvy";
          active_w = "1920";
          active_h = "1294";
          readout_orientation = "0";
          line_length = "2250";
          inherent_gain = "1";
          pix_clk_hz = "94500000";
          serdes_pix_clk_hz = "375000000";      /* MIPI CSI clock 1500Mhz */
          gain_factor = "10";
          min_gain_val = "0";                   /* dB */
          max_gain_val = "300";                 /* dB */
          step_gain_val = "3";                  /* 0.3 */
          default_gain = "0";
          min_hdr_ratio = "1";
          max_hdr_ratio = "1";
          framerate_factor = "1000000";
          min_framerate = "30000000";
          max_framerate = "30000000";
          step_framerate = "1";
          default_framerate = "30000000";
          exposure_factor = "1000000";
          min_exp_time = "24";                  /* us 1 line */
          max_exp_time = "33333";
          step_exp_time = "1";
          default_exp_time = "33333";           /* us */
          embedded_metadata_height = "0";
        };
        mode3 {
          /*mode ISX021_MODE_1920X1280_CROP_30FPS  for Front and Rear Embedded data */
          mclk_khz = "24000";
          num_lanes = "4";
          tegra_sinterface = "serial_c";
          vc_id = "0";
          discontinuous_clk = "no";
          dpcm_enable = "false";
          cil_settletime = "0";
          dynamic_pixel_bit_depth = "16";
          csi_pixel_bit_depth = "16";
          mode_type = "yuv";
          pixel_phase = "uyvy";
          active_w = "1920";
          active_h = "1295";
          readout_orientation = "0";
          line_length = "2250";
          inherent_gain = "1";
          pix_clk_hz = "94500000";
          serdes_pix_clk_hz = "375000000";      /* MIPI CSI clock 1500Mhz */
          gain_factor = "10";
          min_gain_val = "0";                   /* dB */
          max_gain_val = "300";                 /* dB */
          step_gain_val = "3";                  /* 0.3 */
          default_gain = "0";
          min_hdr_ratio = "1";
          max_hdr_ratio = "1";
          framerate_factor = "1000000";
          min_framerate = "30000000";
          max_framerate = "30000000";
          step_framerate = "1";
          default_framerate = "30000000";
          exposure_factor = "1000000";
          min_exp_time = "24";                  /* us 1 line */
          max_exp_time = "33333";
          step_exp_time = "1";
          default_exp_time = "33333";           /* us */
          embedded_metadata_height = "0";
        };

        ports {
          #address-cells = <1>;
          #size-cells = <0>;
          port@0 {
            reg = <0>;
            isx021_out2: endpoint {
              vc-id = <0>;
              port-index = <2>;
              bus-width = <4>;
              remote-endpoint = <&csi_in2>;
            };
          };
        };

        gmsl-link {
          src-csi-port = "b";           /* Port at which sensor is connected to its serializer device. */
          dst-csi-port = "a";           /* Destination CSI port on the Jetson side, connected at deserializer. */
          serdes-csi-link = "a";        /* GMSL link sensor/serializer connected */
          csi-mode = "1x4";             /*  to sensor CSI mode. */
          st-vc = <0>;                  /* Sensor source default VC ID: 0 unless overridden by sensor. */
          vc-id = <0>;                  /* Destination VC ID, assigned to sensor stream by deserializer. */
          num-lanes = <4>;              /* Number of CSI lanes used. */
          streams = "ued-u1", "yuv8";   /* Types of streams sensor is streaming. */
        };
      };
    };
  };
  fragment@93{
    //cami2c/i2c@2
    target-path = "/bus@0/i2c@c250000/tca9546@70/i2c@2";
    __overlay__ {
      i2c-mux,deselect-on-exit;
      #address-cells = <1>;
      #size-cells = <0>;
      status = "okay";
      reg = <2>;

      dser_2: max9296@48 {
        compatible = "nvidia,tier4_max9296";
        reg = <0x48>;
        status = "okay";
        csi-mode = "2x4";
        max-src = <2>;
        //reset-gpios = <&tegra_main_gpio CAM0_PWDN GPIO_ACTIVE_HIGH>;
        //reset-gpios = <&tegra_main_gpio 0x3E 0x0>;
      };

      max9295_prim@62 {
        compatible = "nvidia,tier4_max9295";
        status = "okay";
        reg = <0x62>;
        is-prim-ser;
      };
      max9295_ser_e: max9295_a@42 {
        compatible = "nvidia,tier4_max9295";
        reg = <0x42>;
        nvidia,gmsl-dser-device = <&dser_2>;
      };

      max9295_ser_f: max9295_b@60 {
        compatible = "nvidia,tier4_max9295";
        status = "okay";
        reg = <0x60>;
        nvidia,gmsl-dser-device = <&dser_2>;
      };

      max20089_c: max20089@29 {
        status = "okay";
        compatible = "maxim,max20089";
        reg = <0x29>;
      };

      isx021_f@1e {
        status = "okay";
        compatible = "nvidia,tier4_isx021";
        def-addr = <0x1a>;
        mclk = "extperiph1";
        clocks = <&bpmp 36U>, <&bpmp 36U>;
        clock-names = "extperiph1", "pllp_grtba";
        nvidia,gmsl-ser-device = <&max9295_ser_f>;
        nvidia,gmsl-dser-device = <&dser_2>;
        nvidia,fpga-device  = <&t4_fpga>;
        nvidia,cam-power-protector  = <&max20089_c>;
        reg = <0x1e>;
        physical_w = "15.0";
        physical_h = "12.5";
        reg_mux = <2>;

        sensor_model ="isx021";
        fsync-mode = "false";
        distortion-correction = "false";
        auto-exposure = "true";
        post_crop_frame_drop = "0";
        use_decibel_gain = "true";

        /* enable CID_SENSOR_MODE_ID for sensor modes selection */
        use_sensor_mode_id = "false";

        mode0 {
          /*mode ISX021_MODE_1920X1280_CROP_30FPS*/
          mclk_khz = "24000";
          num_lanes = "4";
          tegra_sinterface = "serial_e";
          vc_id = "1";
          discontinuous_clk = "no";
          dpcm_enable = "false";
          cil_settletime = "0";
          dynamic_pixel_bit_depth = "16";
          csi_pixel_bit_depth = "16";
          mode_type = "yuv";
          pixel_phase = "uyvy";

          active_w = "1920";
          active_h = "1280";
          readout_orientation = "0";
          line_length = "2250";
          inherent_gain = "1";

          pix_clk_hz = "94500000";
          serdes_pix_clk_hz = "375000000";    // MIPI CSI clock 1500Mhz

          gain_factor = "10";
          min_gain_val = "0";                   /* dB */
          max_gain_val = "300";                 /* dB */
          step_gain_val = "3";                  /* 0.3 */
          default_gain = "0";
          min_hdr_ratio = "1";
          max_hdr_ratio = "1";
          framerate_factor = "1000000";
          min_framerate = "30000000";
          max_framerate = "30000000";
          step_framerate = "1";
          default_framerate = "30000000";
          exposure_factor = "1000000";
          min_exp_time = "24";                  /* us 1 line */
          max_exp_time = "33333";
          step_exp_time = "1";
          default_exp_time = "33333";           /* us */
          embedded_metadata_height = "0";
        };
        mode1 {
          /*mode ISX021_MODE_1920X1280_CROP_30FPS  for Front Embedded data */
          mclk_khz = "24000";
          num_lanes = "4";
          tegra_sinterface = "serial_e";
          vc_id = "1";
          discontinuous_clk = "no";
          dpcm_enable = "false";
          cil_settletime = "0";
          dynamic_pixel_bit_depth = "16";
          csi_pixel_bit_depth = "16";
          mode_type = "yuv";
          pixel_phase = "uyvy";
          active_w = "1920";
          active_h = "1281";
          readout_orientation = "0";
          line_length = "2250";
          inherent_gain = "1";
          pix_clk_hz = "94500000";
          serdes_pix_clk_hz = "375000000";      /* MIPI CSI clock 1500Mhz */
          gain_factor = "10";
          min_gain_val = "0";                   /* dB */
          max_gain_val = "300";                 /* dB */
          step_gain_val = "3";                  /* 0.3 */
          default_gain = "0";
          min_hdr_ratio = "1";
          max_hdr_ratio = "1";
          framerate_factor = "1000000";
          min_framerate = "30000000";
          max_framerate = "30000000";
          step_framerate = "1";
          default_framerate = "30000000";
          exposure_factor = "1000000";
          min_exp_time = "24";                  /* us 1 line */
          max_exp_time = "33333";
          step_exp_time = "1";
          default_exp_time = "33333";           /* us */
          embedded_metadata_height = "0";
        };
        mode2 {
          /*mode ISX021_MODE_1920X1280_CROP_30FPS  for Rear Embedded data */
          mclk_khz = "24000";
          num_lanes = "4";
          tegra_sinterface = "serial_e";
          vc_id = "1";
          discontinuous_clk = "no";
          dpcm_enable = "false";
          cil_settletime = "0";
          dynamic_pixel_bit_depth = "16";
          csi_pixel_bit_depth = "16";
          mode_type = "yuv";
          pixel_phase = "uyvy";
          active_w = "1920";
          active_h = "1294";
          readout_orientation = "0";
          line_length = "2250";
          inherent_gain = "1";
          pix_clk_hz = "94500000";
          serdes_pix_clk_hz = "375000000";      /* MIPI CSI clock 1500Mhz */
          gain_factor = "10";
          min_gain_val = "0";                   /* dB */
          max_gain_val = "300";                 /* dB */
          step_gain_val = "3";                  /* 0.3 */
          default_gain = "0";
          min_hdr_ratio = "1";
          max_hdr_ratio = "1";
          framerate_factor = "1000000";
          min_framerate = "30000000";
          max_framerate = "30000000";
          step_framerate = "1";
          default_framerate = "30000000";
          exposure_factor = "1000000";
          min_exp_time = "24";                  /* us 1 line */
          max_exp_time = "33333";
          step_exp_time = "1";
          default_exp_time = "33333";           /* us */
          embedded_metadata_height = "0";
        };
        mode3 {
          /*mode ISX021_MODE_1920X1280_CROP_30FPS  for Front and Rear Embedded data */
          mclk_khz = "24000";
          num_lanes = "4";
          tegra_sinterface = "serial_e";
          vc_id = "1";
          discontinuous_clk = "no";
          dpcm_enable = "false";
          cil_settletime = "0";
          dynamic_pixel_bit_depth = "16";
          csi_pixel_bit_depth = "16";
          mode_type = "yuv";
          pixel_phase = "uyvy";
          active_w = "1920";
          active_h = "1295";
          readout_orientation = "0";
          line_length = "2250";
          inherent_gain = "1";
          pix_clk_hz = "94500000";
          serdes_pix_clk_hz = "375000000";      /* MIPI CSI clock 1500Mhz */
          gain_factor = "10";
          min_gain_val = "0";                   /* dB */
          max_gain_val = "300";                 /* dB */
          step_gain_val = "3";                  /* 0.3 */
          default_gain = "0";
          min_hdr_ratio = "1";
          max_hdr_ratio = "1";
          framerate_factor = "1000000";
          min_framerate = "30000000";
          max_framerate = "30000000";
          step_framerate = "1";
          default_framerate = "30000000";
          exposure_factor = "1000000";
          min_exp_time = "24";                  /* us 1 line */
          max_exp_time = "33333";
          step_exp_time = "1";
          default_exp_time = "33333";           /* us */
          embedded_metadata_height = "0";
        };

        ports {
          #address-cells = <1>;
          #size-cells = <0>;
          port@0 {
            reg = <0>;
            isx021_out5: endpoint {
              vc-id = <1>;
              port-index = <4>;
              bus-width = <4>;
              remote-endpoint = <&csi_in5>;
            };
          };
        };

        gmsl-link {
          src-csi-port = "b";           /* Port at which sensor is connected to its serializer device. */
          dst-csi-port = "a";           /* Destination CSI port on the Jetson side, connected at deserializer. */
           serdes-csi-link = "b";        /* GMSL link sensor/serializer connected */
          csi-mode = "1x4";             /*  to sensor CSI mode. */
          st-vc = <0>;                  /* Sensor source default VC ID: 0 unless overridden by sensor. */
          vc-id = <1>;                  /* Destination VC ID, assigned to sensor stream by deserializer. */
          num-lanes = <4>;              /* Number of CSI lanes used. */
          streams = "ued-u1", "yuv8";   /* Types of streams sensor is streaming. */
        };
      };
      isx021_e@1d {
        status = "okay";
        compatible = "nvidia,tier4_isx021";
        def-addr = <0x1a>;
        mclk = "extperiph1";
        clocks = <&bpmp 36U>, <&bpmp 36U>;
        clock-names = "extperiph1", "pllp_grtba";
        nvidia,gmsl-ser-device = <&max9295_ser_e>;
        nvidia,gmsl-dser-device = <&dser_2>;
        nvidia,fpga-device  = <&t4_fpga>;
        nvidia,cam-power-protector  = <&max20089_c>;
        reg = <0x1d>;
        physical_w = "15.0";
        physical_h = "12.5";
        reg_mux = <2>;

        sensor_model ="isx021";
        fsync-mode = "false";
        distortion-correction = "false";
        auto-exposure = "true";
        post_crop_frame_drop = "0";
        use_decibel_gain = "true";

        /* enable CID_SENSOR_MODE_ID for sensor modes selection */
        use_sensor_mode_id = "false";

        mode0 {
          /*mode ISX021_MODE_1920X1280_CROP_30FPS*/
          mclk_khz = "24000";
          num_lanes = "4";
          tegra_sinterface = "serial_e";
          vc_id = "0";
          discontinuous_clk = "no";
          dpcm_enable = "false";
          cil_settletime = "0";
          dynamic_pixel_bit_depth = "16";
          csi_pixel_bit_depth = "16";
          mode_type = "yuv";
          pixel_phase = "uyvy";

          active_w = "1920";
          active_h = "1280";
          readout_orientation = "0";
          line_length = "2250";
          inherent_gain = "1";

          pix_clk_hz = "94500000";
          serdes_pix_clk_hz = "375000000";    // MIPI CSI clock 1500Mhz

          gain_factor = "10";
          min_gain_val = "0";                   /* dB */
          max_gain_val = "300";                 /* dB */
          step_gain_val = "3";                  /* 0.3 */
          default_gain = "0";
          min_hdr_ratio = "1";
          max_hdr_ratio = "1";
          framerate_factor = "1000000";
          min_framerate = "30000000";
          max_framerate = "30000000";
          step_framerate = "1";
          default_framerate = "30000000";
          exposure_factor = "1000000";
          min_exp_time = "24";                  /* us 1 line */
          max_exp_time = "33333";
          step_exp_time = "1";
          default_exp_time = "33333";           /* us */
          embedded_metadata_height = "0";
        };
        mode1 {
          /*mode ISX021_MODE_1920X1280_CROP_30FPS  for Front Embedded data */
          mclk_khz = "24000";
          num_lanes = "4";
          tegra_sinterface = "serial_e";
          vc_id = "0";
          discontinuous_clk = "no";
          dpcm_enable = "false";
          cil_settletime = "0";
          dynamic_pixel_bit_depth = "16";
          csi_pixel_bit_depth = "16";
          mode_type = "yuv";
          pixel_phase = "uyvy";
          active_w = "1920";
          active_h = "1281";
          readout_orientation = "0";
          line_length = "2250";
          inherent_gain = "1";
          pix_clk_hz = "94500000";
          serdes_pix_clk_hz = "375000000";      /* MIPI CSI clock 1500Mhz */
          gain_factor = "10";
          min_gain_val = "0";                   /* dB */
          max_gain_val = "300";                 /* dB */
          step_gain_val = "3";                  /* 0.3 */
          default_gain = "0";
          min_hdr_ratio = "1";
          max_hdr_ratio = "1";
          framerate_factor = "1000000";
          min_framerate = "30000000";
          max_framerate = "30000000";
          step_framerate = "1";
          default_framerate = "30000000";
          exposure_factor = "1000000";
          min_exp_time = "24";                  /* us 1 line */
          max_exp_time = "33333";
          step_exp_time = "1";
          default_exp_time = "33333";           /* us */
          embedded_metadata_height = "0";
        };
        mode2 {
          /*mode ISX021_MODE_1920X1280_CROP_30FPS  for Rear Embedded data */
          mclk_khz = "24000";
          num_lanes = "4";
          tegra_sinterface = "serial_e";
          vc_id = "0";
          discontinuous_clk = "no";
          dpcm_enable = "false";
          cil_settletime = "0";
          dynamic_pixel_bit_depth = "16";
          csi_pixel_bit_depth = "16";
          mode_type = "yuv";
          pixel_phase = "uyvy";
          active_w = "1920";
          active_h = "1294";
          readout_orientation = "0";
          line_length = "2250";
          inherent_gain = "1";
          pix_clk_hz = "94500000";
          serdes_pix_clk_hz = "375000000";      /* MIPI CSI clock 1500Mhz */
          gain_factor = "10";
          min_gain_val = "0";                   /* dB */
          max_gain_val = "300";                 /* dB */
          step_gain_val = "3";                  /* 0.3 */
          default_gain = "0";
          min_hdr_ratio = "1";
          max_hdr_ratio = "1";
          framerate_factor = "1000000";
          min_framerate = "30000000";
          max_framerate = "30000000";
          step_framerate = "1";
          default_framerate = "30000000";
          exposure_factor = "1000000";
          min_exp_time = "24";                  /* us 1 line */
          max_exp_time = "33333";
          step_exp_time = "1";
          default_exp_time = "33333";           /* us */
          embedded_metadata_height = "0";
        };
        mode3 {
          /*mode ISX021_MODE_1920X1280_CROP_30FPS  for Front and Rear Embedded data */
          mclk_khz = "24000";
          num_lanes = "4";
          tegra_sinterface = "serial_e";
          vc_id = "0";
          discontinuous_clk = "no";
          dpcm_enable = "false";
          cil_settletime = "0";
          dynamic_pixel_bit_depth = "16";
          csi_pixel_bit_depth = "16";
          mode_type = "yuv";
          pixel_phase = "uyvy";
          active_w = "1920";
          active_h = "1295";
          readout_orientation = "0";
          line_length = "2250";
          inherent_gain = "1";
          pix_clk_hz = "94500000";
          serdes_pix_clk_hz = "375000000";      /* MIPI CSI clock 1500Mhz */
          gain_factor = "10";
          min_gain_val = "0";                   /* dB */
          max_gain_val = "300";                 /* dB */
          step_gain_val = "3";                  /* 0.3 */
          default_gain = "0";
          min_hdr_ratio = "1";
          max_hdr_ratio = "1";
          framerate_factor = "1000000";
          min_framerate = "30000000";
          max_framerate = "30000000";
          step_framerate = "1";
          default_framerate = "30000000";
          exposure_factor = "1000000";
          min_exp_time = "24";                  /* us 1 line */
          max_exp_time = "33333";
          step_exp_time = "1";
          default_exp_time = "33333";           /* us */
          embedded_metadata_height = "0";
        };

        ports {
          #address-cells = <1>;
          #size-cells = <0>;
          port@0 {
            reg = <0>;
            isx021_out4: endpoint {
              vc-id = <0>;
              port-index = <4>;
              bus-width = <4>;
              remote-endpoint = <&csi_in4>;
            };
          };
        };

        gmsl-link {
          src-csi-port = "b";           /* Port at which sensor is connected to its serializer device. */
          dst-csi-port = "a";           /* Destination CSI port on the Jetson side, connected at deserializer. */
          serdes-csi-link = "a";        /* GMSL link sensor/serializer connected */
          csi-mode = "1x4";             /*  to sensor CSI mode. */
          st-vc = <0>;                  /* Sensor source default VC ID: 0 unless overridden by sensor. */
          vc-id = <0>;                  /* Destination VC ID, assigned to sensor stream by deserializer. */
          num-lanes = <4>;              /* Number of CSI lanes used. */
          streams = "ued-u1", "yuv8";   /* Types of streams sensor is streaming. */
        };
      };
    };
  };
  fragment@94{
    //cami2c/i2c@3
    target-path = "/bus@0/i2c@c250000/tca9546@70/i2c@3";
    __overlay__ {
      i2c-mux,deselect-on-exit;
      #address-cells = <1>;
      #size-cells = <0>;
      status = "okay";
      reg = <3>;

      dser_3: max9296@48 {
        compatible = "nvidia,tier4_max9296";
        reg = <0x48>;
        status = "okay";
        csi-mode = "2x4";
        max-src = <2>;
        //reset-gpios = <&tegra_main_gpio CAM0_PWDN GPIO_ACTIVE_HIGH>;
        //reset-gpios = <&tegra_main_gpio 0x3E 0x0>;
      };

      max9295_prim@62 {
        compatible = "nvidia,tier4_max9295";
        status = "okay";
        reg = <0x62>;
        is-prim-ser;
      };
      max9295_ser_g: max9295_a@42 {
        compatible = "nvidia,tier4_max9295";
        reg = <0x42>;
        nvidia,gmsl-dser-device = <&dser_3>;
      };

      max9295_ser_h: max9295_b@60 {
        compatible = "nvidia,tier4_max9295";
        status = "okay";
        reg = <0x60>;
        nvidia,gmsl-dser-device = <&dser_3>;
      };

      max20089_d: max20089@29 {
        status = "okay";
        compatible = "maxim,max20089";
        reg = <0x29>;
      };

      isx021_h@1e {
        status = "okay";
        compatible = "nvidia,tier4_isx021";
        def-addr = <0x1a>;
        mclk = "extperiph1";
        clocks = <&bpmp 36U>, <&bpmp 36U>;
        clock-names = "extperiph1", "pllp_grtba";
        nvidia,gmsl-ser-device = <&max9295_ser_h>;
        nvidia,gmsl-dser-device = <&dser_3>;
        nvidia,fpga-device  = <&t4_fpga>;
        nvidia,cam-power-protector  = <&max20089_d>;
        reg = <0x1e>;
        physical_w = "15.0";
        physical_h = "12.5";
        reg_mux = <3>;

        sensor_model ="isx021";
        fsync-mode = "false";
        distortion-correction = "false";
        auto-exposure = "true";
        post_crop_frame_drop = "0";
        use_decibel_gain = "true";

        /* enable CID_SENSOR_MODE_ID for sensor modes selection */
        use_sensor_mode_id = "false";

        mode0 {
          /*mode ISX021_MODE_1920X1280_CROP_30FPS*/
          mclk_khz = "24000";
          num_lanes = "4";
          tegra_sinterface = "serial_g";
          vc_id = "1";
          discontinuous_clk = "no";
          dpcm_enable = "false";
          cil_settletime = "0";
          dynamic_pixel_bit_depth = "16";
          csi_pixel_bit_depth = "16";
          mode_type = "yuv";
          pixel_phase = "uyvy";

          active_w = "1920";
          active_h = "1280";
          readout_orientation = "0";
          line_length = "2250";
          inherent_gain = "1";

          pix_clk_hz = "94500000";
          serdes_pix_clk_hz = "375000000";    // MIPI CSI clock 1500Mhz

          gain_factor = "10";
          min_gain_val = "0";                   /* dB */
          max_gain_val = "300";                 /* dB */
          step_gain_val = "3";                  /* 0.3 */
          default_gain = "0";
          min_hdr_ratio = "1";
          max_hdr_ratio = "1";
          framerate_factor = "1000000";
          min_framerate = "30000000";
          max_framerate = "30000000";
          step_framerate = "1";
          default_framerate = "30000000";
          exposure_factor = "1000000";
          min_exp_time = "24";                  /* us 1 line */
          max_exp_time = "33333";
          step_exp_time = "1";
          default_exp_time = "33333";           /* us */
          embedded_metadata_height = "0";
        };
        mode1 {
          /*mode ISX021_MODE_1920X1280_CROP_30FPS  for Front Embedded data */
          mclk_khz = "24000";
          num_lanes = "4";
          tegra_sinterface = "serial_g";
          vc_id = "1";
          discontinuous_clk = "no";
          dpcm_enable = "false";
          cil_settletime = "0";
          dynamic_pixel_bit_depth = "16";
          csi_pixel_bit_depth = "16";
          mode_type = "yuv";
          pixel_phase = "uyvy";
          active_w = "1920";
          active_h = "1281";
          readout_orientation = "0";
          line_length = "2250";
          inherent_gain = "1";
          pix_clk_hz = "94500000";
          serdes_pix_clk_hz = "375000000";      /* MIPI CSI clock 1500Mhz */
          gain_factor = "10";
          min_gain_val = "0";                   /* dB */
          max_gain_val = "300";                 /* dB */
          step_gain_val = "3";                  /* 0.3 */
          default_gain = "0";
          min_hdr_ratio = "1";
          max_hdr_ratio = "1";
          framerate_factor = "1000000";
          min_framerate = "30000000";
          max_framerate = "30000000";
          step_framerate = "1";
          default_framerate = "30000000";
          exposure_factor = "1000000";
          min_exp_time = "24";                  /* us 1 line */
          max_exp_time = "33333";
          step_exp_time = "1";
          default_exp_time = "33333";           /* us */
          embedded_metadata_height = "0";
        };
        mode2 {
          /*mode ISX021_MODE_1920X1280_CROP_30FPS  for Rear Embedded data */
          mclk_khz = "24000";
          num_lanes = "4";
          tegra_sinterface = "serial_g";
          vc_id = "1";
          discontinuous_clk = "no";
          dpcm_enable = "false";
          cil_settletime = "0";
          dynamic_pixel_bit_depth = "16";
          csi_pixel_bit_depth = "16";
          mode_type = "yuv";
          pixel_phase = "uyvy";
          active_w = "1920";
          active_h = "1294";
          readout_orientation = "0";
          line_length = "2250";
          inherent_gain = "1";
          pix_clk_hz = "94500000";
          serdes_pix_clk_hz = "375000000";      /* MIPI CSI clock 1500Mhz */
          gain_factor = "10";
          min_gain_val = "0";                   /* dB */
          max_gain_val = "300";                 /* dB */
          step_gain_val = "3";                  /* 0.3 */
          default_gain = "0";
          min_hdr_ratio = "1";
          max_hdr_ratio = "1";
          framerate_factor = "1000000";
          min_framerate = "30000000";
          max_framerate = "30000000";
          step_framerate = "1";
          default_framerate = "30000000";
          exposure_factor = "1000000";
          min_exp_time = "24";                  /* us 1 line */
          max_exp_time = "33333";
          step_exp_time = "1";
          default_exp_time = "33333";           /* us */
          embedded_metadata_height = "0";
        };
        mode3 {
          /*mode ISX021_MODE_1920X1280_CROP_30FPS  for Front and Rear Embedded data */
          mclk_khz = "24000";
          num_lanes = "4";
          tegra_sinterface = "serial_g";
          vc_id = "1";
          discontinuous_clk = "no";
          dpcm_enable = "false";
          cil_settletime = "0";
          dynamic_pixel_bit_depth = "16";
          csi_pixel_bit_depth = "16";
          mode_type = "yuv";
          pixel_phase = "uyvy";
          active_w = "1920";
          active_h = "1295";
          readout_orientation = "0";
          line_length = "2250";
          inherent_gain = "1";
          pix_clk_hz = "94500000";
          serdes_pix_clk_hz = "375000000";      /* MIPI CSI clock 1500Mhz */
          gain_factor = "10";
          min_gain_val = "0";                   /* dB */
          max_gain_val = "300";                 /* dB */
          step_gain_val = "3";                  /* 0.3 */
          default_gain = "0";
          min_hdr_ratio = "1";
          max_hdr_ratio = "1";
          framerate_factor = "1000000";
          min_framerate = "30000000";
          max_framerate = "30000000";
          step_framerate = "1";
          default_framerate = "30000000";
          exposure_factor = "1000000";
          min_exp_time = "24";                  /* us 1 line */
          max_exp_time = "33333";
          step_exp_time = "1";
          default_exp_time = "33333";           /* us */
          embedded_metadata_height = "0";
        };

        ports {
          #address-cells = <1>;
          #size-cells = <0>;
          port@0 {
            reg = <0>;
            isx021_out7: endpoint {
              vc-id = <1>;
              port-index = <6>;
              bus-width = <4>;
              remote-endpoint = <&csi_in7>;
            };
          };
        };

        gmsl-link {
          src-csi-port = "b";           /* Port at which sensor is connected to its serializer device. */
          dst-csi-port = "a";           /* Destination CSI port on the Jetson side, connected at deserializer. */
           serdes-csi-link = "b";        /* GMSL link sensor/serializer connected */
          csi-mode = "1x4";             /*  to sensor CSI mode. */
          st-vc = <0>;                  /* Sensor source default VC ID: 0 unless overridden by sensor. */
          vc-id = <1>;                  /* Destination VC ID, assigned to sensor stream by deserializer. */
          num-lanes = <4>;              /* Number of CSI lanes used. */
          streams = "ued-u1", "yuv8";   /* Types of streams sensor is streaming. */
        };
      };
      isx021_g@1d {
        status = "okay";
        compatible = "nvidia,tier4_isx021";
        def-addr = <0x1a>;
        mclk = "extperiph1";
        clocks = <&bpmp 36U>, <&bpmp 36U>;
        clock-names = "extperiph1", "pllp_grtba";
        nvidia,gmsl-ser-device = <&max9295_ser_g>;
        nvidia,gmsl-dser-device = <&dser_3>;
        nvidia,fpga-device  = <&t4_fpga>;
        nvidia,cam-power-protector  = <&max20089_d>;
        reg = <0x1d>;
        physical_w = "15.0";
        physical_h = "12.5";
        reg_mux = <3>;

        sensor_model ="isx021";
        fsync-mode = "false";
        distortion-correction = "false";
        auto-exposure = "true";
        post_crop_frame_drop = "0";
        use_decibel_gain = "true";

        /* enable CID_SENSOR_MODE_ID for sensor modes selection */
        use_sensor_mode_id = "false";

        mode0 {
          /*mode ISX021_MODE_1920X1280_CROP_30FPS*/
          mclk_khz = "24000";
          num_lanes = "4";
          tegra_sinterface = "serial_g";
          vc_id = "0";
          discontinuous_clk = "no";
          dpcm_enable = "false";
          cil_settletime = "0";
          dynamic_pixel_bit_depth = "16";
          csi_pixel_bit_depth = "16";
          mode_type = "yuv";
          pixel_phase = "uyvy";

          active_w = "1920";
          active_h = "1280";
          readout_orientation = "0";
          line_length = "2250";
          inherent_gain = "1";

          pix_clk_hz = "94500000";
          serdes_pix_clk_hz = "375000000";    // MIPI CSI clock 1500Mhz

          gain_factor = "10";
          min_gain_val = "0";                   /* dB */
          max_gain_val = "300";                 /* dB */
          step_gain_val = "3";                  /* 0.3 */
          default_gain = "0";
          min_hdr_ratio = "1";
          max_hdr_ratio = "1";
          framerate_factor = "1000000";
          min_framerate = "30000000";
          max_framerate = "30000000";
          step_framerate = "1";
          default_framerate = "30000000";
          exposure_factor = "1000000";
          min_exp_time = "24";                  /* us 1 line */
          max_exp_time = "33333";
          step_exp_time = "1";
          default_exp_time = "33333";           /* us */
          embedded_metadata_height = "0";
        };
        mode1 {
          /*mode ISX021_MODE_1920X1280_CROP_30FPS  for Front Embedded data */
          mclk_khz = "24000";
          num_lanes = "4";
          tegra_sinterface = "serial_g";
          vc_id = "0";
          discontinuous_clk = "no";
          dpcm_enable = "false";
          cil_settletime = "0";
          dynamic_pixel_bit_depth = "16";
          csi_pixel_bit_depth = "16";
          mode_type = "yuv";
          pixel_phase = "uyvy";
          active_w = "1920";
          active_h = "1281";
          readout_orientation = "0";
          line_length = "2250";
          inherent_gain = "1";
          pix_clk_hz = "94500000";
          serdes_pix_clk_hz = "375000000";      /* MIPI CSI clock 1500Mhz */
          gain_factor = "10";
          min_gain_val = "0";                   /* dB */
          max_gain_val = "300";                 /* dB */
          step_gain_val = "3";                  /* 0.3 */
          default_gain = "0";
          min_hdr_ratio = "1";
          max_hdr_ratio = "1";
          framerate_factor = "1000000";
          min_framerate = "30000000";
          max_framerate = "30000000";
          step_framerate = "1";
          default_framerate = "30000000";
          exposure_factor = "1000000";
          min_exp_time = "24";                  /* us 1 line */
          max_exp_time = "33333";
          step_exp_time = "1";
          default_exp_time = "33333";           /* us */
          embedded_metadata_height = "0";
        };
        mode2 {
          /*mode ISX021_MODE_1920X1280_CROP_30FPS  for Rear Embedded data */
          mclk_khz = "24000";
          num_lanes = "4";
          tegra_sinterface = "serial_g";
          vc_id = "0";
          discontinuous_clk = "no";
          dpcm_enable = "false";
          cil_settletime = "0";
          dynamic_pixel_bit_depth = "16";
          csi_pixel_bit_depth = "16";
          mode_type = "yuv";
          pixel_phase = "uyvy";
          active_w = "1920";
          active_h = "1294";
          readout_orientation = "0";
          line_length = "2250";
          inherent_gain = "1";
          pix_clk_hz = "94500000";
          serdes_pix_clk_hz = "375000000";      /* MIPI CSI clock 1500Mhz */
          gain_factor = "10";
          min_gain_val = "0";                   /* dB */
          max_gain_val = "300";                 /* dB */
          step_gain_val = "3";                  /* 0.3 */
          default_gain = "0";
          min_hdr_ratio = "1";
          max_hdr_ratio = "1";
          framerate_factor = "1000000";
          min_framerate = "30000000";
          max_framerate = "30000000";
          step_framerate = "1";
          default_framerate = "30000000";
          exposure_factor = "1000000";
          min_exp_time = "24";                  /* us 1 line */
          max_exp_time = "33333";
          step_exp_time = "1";
          default_exp_time = "33333";           /* us */
          embedded_metadata_height = "0";
        };
        mode3 {
          /*mode ISX021_MODE_1920X1280_CROP_30FPS  for Front and Rear Embedded data */
          mclk_khz = "24000";
          num_lanes = "4";
          tegra_sinterface = "serial_g";
          vc_id = "0";
          discontinuous_clk = "no";
          dpcm_enable = "false";
          cil_settletime = "0";
          dynamic_pixel_bit_depth = "16";
          csi_pixel_bit_depth = "16";
          mode_type = "yuv";
          pixel_phase = "uyvy";
          active_w = "1920";
          active_h = "1295";
          readout_orientation = "0";
          line_length = "2250";
          inherent_gain = "1";
          pix_clk_hz = "94500000";
          serdes_pix_clk_hz = "375000000";      /* MIPI CSI clock 1500Mhz */
          gain_factor = "10";
          min_gain_val = "0";                   /* dB */
          max_gain_val = "300";                 /* dB */
          step_gain_val = "3";                  /* 0.3 */
          default_gain = "0";
          min_hdr_ratio = "1";
          max_hdr_ratio = "1";
          framerate_factor = "1000000";
          min_framerate = "30000000";
          max_framerate = "30000000";
          step_framerate = "1";
          default_framerate = "30000000";
          exposure_factor = "1000000";
          min_exp_time = "24";                  /* us 1 line */
          max_exp_time = "33333";
          step_exp_time = "1";
          default_exp_time = "33333";           /* us */
          embedded_metadata_height = "0";
        };

        ports {
          #address-cells = <1>;
          #size-cells = <0>;
          port@0 {
            reg = <0>;
            isx021_out6: endpoint {
              vc-id = <0>;
              port-index = <6>;
              bus-width = <4>;
              remote-endpoint = <&csi_in6>;
            };
          };
        };

        gmsl-link {
          src-csi-port = "b";           /* Port at which sensor is connected to its serializer device. */
          dst-csi-port = "a";           /* Destination CSI port on the Jetson side, connected at deserializer. */
          serdes-csi-link = "a";        /* GMSL link sensor/serializer connected */
          csi-mode = "1x4";             /*  to sensor CSI mode. */
          st-vc = <0>;                  /* Sensor source default VC ID: 0 unless overridden by sensor. */
          vc-id = <0>;                  /* Destination VC ID, assigned to sensor stream by deserializer. */
          num-lanes = <4>;              /* Number of CSI lanes used. */
          streams = "ued-u1", "yuv8";   /* Types of streams sensor is streaming. */
        };
      };
    };
  };

// -----  FPGA -----

  fragment@100{
    target-path = "/bus@0/i2c@3180000";
    __overlay__ {
     t4_fpga: tier4_fpga@66 {
        compatible = "nvidia,tier4_fpga";
        reg = <0x66>;
        status = "okay";
      };
    };
  };

};

